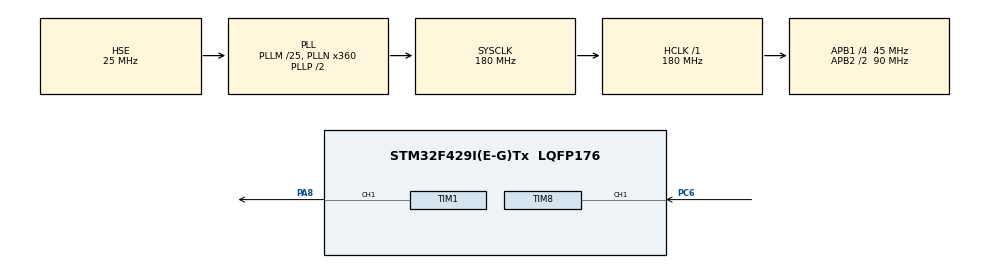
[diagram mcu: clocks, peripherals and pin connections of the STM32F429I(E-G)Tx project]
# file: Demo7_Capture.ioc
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Mcu.Family=STM32F4
Mcu.Name=STM32F429I(E-G)Tx
Mcu.Package=LQFP176
NVIC.PriorityGroup=NVIC_PRIORITYGROUP_2
NVIC.TIM8_CC_IRQn=true\:0\:1\:false\:false\:true\:true\:false
NVIC.TIM8_UP_TIM13_IRQn=true\:0\:2\:false\:false\:true\:true\:false
PA13.Mode=Serial_Wire
PA13.Signal=SYS_JTMS-SWDIO
PA14.Mode=Serial_Wire
PA14.Signal=SYS_JTCK-SWCLK
PA8.GPIO_PuPd=GPIO_NOPULL
PA8.GPIO_Speed=GPIO_SPEED_FREQ_HIGH
PA8.Signal=S_TIM1_CH1
PC6.GPIO_PuPd=GPIO_NOPULL
PC6.GPIO_Speed=GPIO_SPEED_FREQ_VERY_HIGH
PC6.Signal=S_TIM8_CH1
PH0/OSC_IN.Mode=HSE-External-Oscillator
PH0/OSC_IN.Signal=RCC_OSC_IN
PH1/OSC_OUT.Mode=HSE-External-Oscillator
PH1/OSC_OUT.Signal=RCC_OSC_OUT
ProjectManager.HeapSize=0x200
ProjectManager.StackSize=0x400
ProjectManager.TargetToolchain=MDK-ARM V5
RCC.48MHZClocksFreq_Value=90000000
RCC.AHBFreq_Value=180000000
RCC.APB1CLKDivider=RCC_HCLK_DIV4
RCC.APB1Freq_Value=45000000
RCC.APB1TimFreq_Value=90000000
RCC.APB2CLKDivider=RCC_HCLK_DIV2
RCC.APB2Freq_Value=90000000
RCC.APB2TimFreq_Value=180000000
RCC.CortexFreq_Value=180000000
RCC.HCLKFreq_Value=180000000
RCC.HSE_VALUE=25000000
RCC.HSI_VALUE=16000000
RCC.LSE_VALUE=32768
RCC.PLLM=25
RCC.PLLN=360
RCC.PLLSourceVirtual=RCC_PLLSOURCE_HSE
RCC.SYSCLKFreq_VALUE=180000000
RCC.SYSCLKSource=RCC_SYSCLKSOURCE_PLLCLK
RCC.VCOOutputFreq_Value=360000000
SH.S_TIM1_CH1.0=TIM1_CH1,PWM Generation1 CH1
SH.S_TIM8_CH1.0=TIM8_CH1,TriggerSource_TI1FP1
SH.S_TIM8_CH1.1=TIM8_CH1,Input_Capture1_from_TI1
SH.S_TIM8_CH1.2=TIM8_CH1,Input_Capture2_from_TI1
TIM1.AutoReloadPreload=TIM_AUTORELOAD_PRELOAD_ENABLE
TIM1.Channel-PWM\ Generation1\ CH1=TIM_CHANNEL_1
TIM1.OC1Preload_PWM=ENABLE
TIM1.Period=18000-1
TIM1.Prescaler=1000-1
TIM1.Pulse-PWM\ Generation1\ CH1=9000
TIM8.AutoReloadPreload=TIM_AUTORELOAD_PRELOAD_ENABLE
TIM8.Channel-Input_Capture1_from_TI1=TIM_CHANNEL_1
TIM8.Channel-Input_Capture2_from_TI1=TIM_CHANNEL_2
TIM8.CounterMode=TIM_COUNTERMODE_UP
TIM8.ICPolarity_CH2=TIM_INPUTCHANNELPOLARITY_FALLING
TIM8.Period=0xffff
VP_TIM8_VS_ClockSourceINT.Mode=Internal
VP_TIM8_VS_ControllerModeReset.Mode=Reset Mode
board=custom

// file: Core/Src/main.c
/* USER CODE BEGIN Header */
/**
  ******************************************************************************
  * @file           : main.c
  * @brief          : Main program body
  ******************************************************************************
  * @attention
  *
  * <h2><center>&copy; Copyright (c) 2021 STMicroelectronics.
  * All rights reserved.</center></h2>
  *
  * This software component is licensed by ST under BSD 3-Clause license,
  * the "License"; You may not use this file except in compliance with the
  * License. You may obtain a copy of the License at:
  *                        opensource.org/licenses/BSD-3-Clause
  *
  ******************************************************************************
  */
/* USER CODE END Header */
#include "main.h"

/* USER CODE BEGIN Includes */
#include "capture.h"
/* USER CODE END Includes */

TIM_HandleTypeDef htim1;
TIM_HandleTypeDef htim8;

void SystemClock_Config(void);
static void MX_GPIO_Init(void);
static void MX_TIM1_Init(void);
static void MX_TIM8_Init(void);

/* USER CODE BEGIN 0 */

uint32_t testResultPulse = 0;
uint32_t testResultPeriod = 0;
uint16_t testInput = 9000;

/* USER CODE END 0 */

int main(void)
{

    /* MCU Configuration--------------------------------------------------------*/

    /* Reset of all peripherals, Initializes the Flash interface and the Systick. */
    HAL_Init();

    /* Configure the system clock */
    SystemClock_Config();

    /* Initialize all configured peripherals */
    MX_GPIO_Init();
    MX_TIM1_Init();
    MX_TIM8_Init();
    /* USER CODE BEGIN 2 */

    HAL_TIM_PWM_Start(&htim1, TIM_CHANNEL_1);   //Enable PWM
    HAL_TIM_IC_Start_IT(&htim8, TIM_CHANNEL_1); //Enable Capture Rising edge
    HAL_TIM_IC_Start_IT(&htim8, TIM_CHANNEL_2); //Enable Capture Falling edge
    __HAL_TIM_ENABLE_IT(&htim8, TIM_IT_UPDATE); //Enable interrupt update
    __HAL_TIM_URS_ENABLE(&htim8);               //Olny overflow generates update interrupt

    /* USER CODE END 2 */

    /* Infinite loop */
    /* USER CODE BEGIN WHILE */
    while (1)
    {
        testResultPulse = (captureTim8.times[0] << 16) + captureTim8.counter[0] + 2;
        testResultPeriod = (captureTim8.times[1] << 16) + captureTim8.counter[1] + 2;
        TIM1->CCR1 = testInput;

        /* USER CODE END WHILE */

    }
}

void SystemClock_Config(void)
{
    RCC_OscInitTypeDef RCC_OscInitStruct = {0};
    RCC_ClkInitTypeDef RCC_ClkInitStruct = {0};

    /** Configure the main internal regulator output voltage
  */
    __HAL_RCC_PWR_CLK_ENABLE();
    __HAL_PWR_VOLTAGESCALING_CONFIG(PWR_REGULATOR_VOLTAGE_SCALE1);
    /** Initializes the RCC Oscillators according to the specified parameters
  * in the RCC_OscInitTypeDef structure.
  */
    RCC_OscInitStruct.OscillatorType = RCC_OSCILLATORTYPE_HSE;
    RCC_OscInitStruct.HSEState = RCC_HSE_ON;
    RCC_OscInitStruct.PLL.PLLState = RCC_PLL_ON;
    RCC_OscInitStruct.PLL.PLLSource = RCC_PLLSOURCE_HSE;
    RCC_OscInitStruct.PLL.PLLM = 25;
    RCC_OscInitStruct.PLL.PLLN = 360;
    RCC_OscInitStruct.PLL.PLLP = RCC_PLLP_DIV2;
    RCC_OscInitStruct.PLL.PLLQ = 4;
    if (HAL_RCC_OscConfig(&RCC_OscInitStruct) != HAL_OK)
    {
        Error_Handler();
    }
    /** Activate the Over-Drive mode
  */
    if (HAL_PWREx_EnableOverDrive() != HAL_OK)
    {
        Error_Handler();
    }
    /** Initializes the CPU, AHB and APB buses clocks
  */
    RCC_ClkInitStruct.ClockType = RCC_CLOCKTYPE_HCLK | RCC_CLOCKTYPE_SYSCLK | RCC_CLOCKTYPE_PCLK1 | RCC_CLOCKTYPE_PCLK2;
    RCC_ClkInitStruct.SYSCLKSource = RCC_SYSCLKSOURCE_PLLCLK;
    RCC_ClkInitStruct.AHBCLKDivider = RCC_SYSCLK_DIV1;
    RCC_ClkInitStruct.APB1CLKDivider = RCC_HCLK_DIV4;
    RCC_ClkInitStruct.APB2CLKDivider = RCC_HCLK_DIV2;

    if (HAL_RCC_ClockConfig(&RCC_ClkInitStruct, FLASH_LATENCY_5) != HAL_OK)
    {
        Error_Handler();
    }
}

static void MX_TIM1_Init(void)
{

    TIM_MasterConfigTypeDef sMasterConfig = {0};
    TIM_OC_InitTypeDef sConfigOC = {0};
    TIM_BreakDeadTimeConfigTypeDef sBreakDeadTimeConfig = {0};

    htim1.Instance = TIM1;
    htim1.Init.Prescaler = 1000 - 1;
    htim1.Init.CounterMode = TIM_COUNTERMODE_UP;
    htim1.Init.Period = 18000 - 1;
    htim1.Init.ClockDivision = TIM_CLOCKDIVISION_DIV1;
    htim1.Init.RepetitionCounter = 0;
    htim1.Init.AutoReloadPreload = TIM_AUTORELOAD_PRELOAD_ENABLE;
    if (HAL_TIM_PWM_Init(&htim1) != HAL_OK)
    {
        Error_Handler();
    }
    sMasterConfig.MasterOutputTrigger = TIM_TRGO_RESET;
    sMasterConfig.MasterSlaveMode = TIM_MASTERSLAVEMODE_DISABLE;
    if (HAL_TIMEx_MasterConfigSynchronization(&htim1, &sMasterConfig) != HAL_OK)
    {
        Error_Handler();
    }
    sConfigOC.OCMode = TIM_OCMODE_PWM1;
    sConfigOC.Pulse = 9000;
    sConfigOC.OCPolarity = TIM_OCPOLARITY_HIGH;
    sConfigOC.OCNPolarity = TIM_OCNPOLARITY_HIGH;
    sConfigOC.OCFastMode = TIM_OCFAST_DISABLE;
    sConfigOC.OCIdleState = TIM_OCIDLESTATE_RESET;
    sConfigOC.OCNIdleState = TIM_OCNIDLESTATE_RESET;
    if (HAL_TIM_PWM_ConfigChannel(&htim1, &sConfigOC, TIM_CHANNEL_1) != HAL_OK)
    {
        Error_Handler();
    }
    sBreakDeadTimeConfig.OffStateRunMode = TIM_OSSR_DISABLE;
    sBreakDeadTimeConfig.OffStateIDLEMode = TIM_OSSI_DISABLE;
    sBreakDeadTimeConfig.LockLevel = TIM_LOCKLEVEL_OFF;
    sBreakDeadTimeConfig.DeadTime = 0;
    sBreakDeadTimeConfig.BreakState = TIM_BREAK_DISABLE;
    sBreakDeadTimeConfig.BreakPolarity = TIM_BREAKPOLARITY_HIGH;
    sBreakDeadTimeConfig.AutomaticOutput = TIM_AUTOMATICOUTPUT_DISABLE;
    if (HAL_TIMEx_ConfigBreakDeadTime(&htim1, &sBreakDeadTimeConfig) != HAL_OK)
    {
        Error_Handler();
    }
    HAL_TIM_MspPostInit(&htim1);
}

static void MX_TIM8_Init(void)
{

    TIM_ClockConfigTypeDef sClockSourceConfig = {0};
    TIM_SlaveConfigTypeDef sSlaveConfig = {0};
    TIM_MasterConfigTypeDef sMasterConfig = {0};
    TIM_IC_InitTypeDef sConfigIC = {0};

    htim8.Instance = TIM8;
    htim8.Init.Prescaler = 0;
    htim8.Init.CounterMode = TIM_COUNTERMODE_UP;
    htim8.Init.Period = 0xffff;
    htim8.Init.ClockDivision = TIM_CLOCKDIVISION_DIV1;
    htim8.Init.RepetitionCounter = 0;
    htim8.Init.AutoReloadPreload = TIM_AUTORELOAD_PRELOAD_ENABLE;
    if (HAL_TIM_Base_Init(&htim8) != HAL_OK)
    {
        Error_Handler();
    }
    sClockSourceConfig.ClockSource = TIM_CLOCKSOURCE_INTERNAL;
    if (HAL_TIM_ConfigClockSource(&htim8, &sClockSourceConfig) != HAL_OK)
    {
        Error_Handler();
    }
    if (HAL_TIM_IC_Init(&htim8) != HAL_OK)
    {
        Error_Handler();
    }
    sSlaveConfig.SlaveMode = TIM_SLAVEMODE_RESET;
    sSlaveConfig.InputTrigger = TIM_TS_TI1FP1;
    sSlaveConfig.TriggerPolarity = TIM_INPUTCHANNELPOLARITY_RISING;
    sSlaveConfig.TriggerFilter = 0;
    if (HAL_TIM_SlaveConfigSynchro(&htim8, &sSlaveConfig) != HAL_OK)
    {
        Error_Handler();
    }
    sMasterConfig.MasterOutputTrigger = TIM_TRGO_RESET;
    sMasterConfig.MasterSlaveMode = TIM_MASTERSLAVEMODE_DISABLE;
    if (HAL_TIMEx_MasterConfigSynchronization(&htim8, &sMasterConfig) != HAL_OK)
    {
        Error_Handler();
    }
    sConfigIC.ICPolarity = TIM_INPUTCHANNELPOLARITY_RISING;
    sConfigIC.ICSelection = TIM_ICSELECTION_DIRECTTI;
    sConfigIC.ICPrescaler = TIM_ICPSC_DIV1;
    sConfigIC.ICFilter = 0;
    if (HAL_TIM_IC_ConfigChannel(&htim8, &sConfigIC, TIM_CHANNEL_1) != HAL_OK)
    {
        Error_Handler();
    }
    sConfigIC.ICPolarity = TIM_INPUTCHANNELPOLARITY_FALLING;
    sConfigIC.ICSelection = TIM_ICSELECTION_INDIRECTTI;
    if (HAL_TIM_IC_ConfigChannel(&htim8, &sConfigIC, TIM_CHANNEL_2) != HAL_OK)
    {
        Error_Handler();
    }
}

static void MX_GPIO_Init(void)
{

    /* GPIO Ports Clock Enable */
    __HAL_RCC_GPIOH_CLK_ENABLE();
    __HAL_RCC_GPIOC_CLK_ENABLE();
    __HAL_RCC_GPIOA_CLK_ENABLE();
}

void Error_Handler(void)
{
    __disable_irq();
    while (1)
    {
    }
}

/************************ (C) COPYRIGHT STMicroelectronics *****END OF FILE****/
